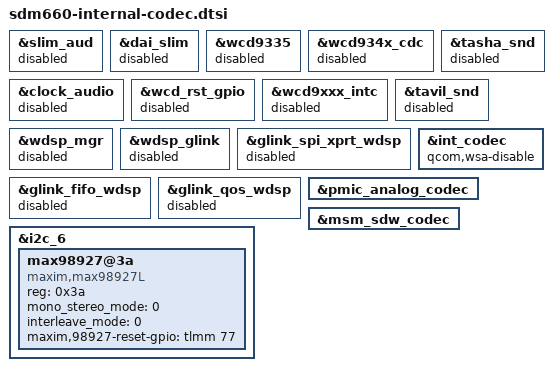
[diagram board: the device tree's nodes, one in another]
/* Copyright (c) 2017, The Linux Foundation. All rights reserved.
 *
 * This program is free software; you can redistribute it and/or modify
 * it under the terms of the GNU General Public License version 2 and
 * only version 2 as published by the Free Software Foundation.
 *
 * This program is distributed in the hope that it will be useful,
 * but WITHOUT ANY WARRANTY; without even the implied warranty of
 * MERCHANTABILITY or FITNESS FOR A PARTICULAR PURPOSE.  See the
 * GNU General Public License for more details.
 */

&slim_aud {
	status = "disabled";
};

&dai_slim {
	status = "disabled";
};

&wcd9335 {
	status = "disabled";
};

&wcd934x_cdc {
	status = "disabled";
};

&clock_audio {
	status = "disabled";
};

&wcd_rst_gpio {
	status = "disabled";
};

&wcd9xxx_intc {
	status = "disabled";
};

&tasha_snd {
	status = "disabled";
};

&tavil_snd {
	status = "disabled";
};

/*&spi_7 {
	status = "disabled";
};*/

&wdsp_mgr {
	status = "disabled";
};

&wdsp_glink {
	status = "disabled";
};

&glink_spi_xprt_wdsp {
	status = "disabled";
};

&glink_fifo_wdsp {
	status = "disabled";
};

&glink_qos_wdsp {
	status = "disabled";
};

&int_codec {
	status = "okay";
	qcom,wsa-disable;
};

&pmic_analog_codec {
	status = "okay";
};

&msm_sdw_codec {
	status = "okay";
};

&i2c_6 { /* SmartPA TI */
	status = "okay";
	max98927@3a {
		compatible = "maxim,max98927L";
		status = "okay";
		reg = <0x3a>;
		mono_stereo_mode = <0>;
		interleave_mode = <0>;
		maxim,98927-reset-gpio = <&tlmm 77 0>;
	};
};
